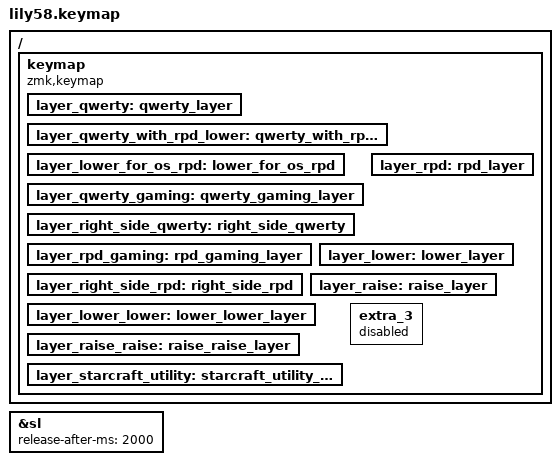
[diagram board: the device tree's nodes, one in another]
#include <behaviors.dtsi>
#include <dt-bindings/zmk/bt.h>
#include <dt-bindings/zmk/keys.h>

// for mouse configuration
#define ZMK_POINTING_DEFAULT_MOVE_VAL 1250
#define ZMK_POINTING_DEFAULT_SCRL_VAL 20
#include <dt-bindings/zmk/pointing.h>

#include "zmk-helpers/helper.h"

#include "keymaps/constants.dtsi"
#include "keymaps/combos/index.dtsi"
#include "keymaps/behaviours/mod-morphs/index.dtsi"
#include "keymaps/behaviours/mod-morphs/rpd-mod-morphs.dtsi"
#include "keymaps/behaviours/tap-holds/timeless-hrm.dtsi"
#include "keymaps/behaviours/tap-holds/index.dtsi"




/*                                      58 KEY MATRIX / LAYOUT MAPPING

  ╭────────────────────────────┬────────────────────────────╮ ╭─────────────────────────────┬─────────────────────────────╮
  │  0   1   2   3   4   5     │      6   7   8   9  10  11 │ │ LT5 LT4 LT3 LT2 LT1 LT0     │     RT0 RT1 RT2 RT3 RT4 RT5 │
  │ 12  13  14  15  16  17     │     18  19  20  21  22  23 │ │ LM5 LM4 LM3 LM2 LM1 LM0     │     RM0 RM1 RM2 RM3 RM4 RM5 │
  │ 24  25  26  27  28  29     │     30  31  32  33  34  35 │ │ LB5 LB4 LB3 LB2 LB1 LB0     │     RB0 RB1 RB2 RB3 RB4 RB5 │
  │ 36  37  38  39  40  41  42 │ 43  44  45  46  47  48  49 │ │ LF5 LF4 LF3 LF2 LF1 LF0 LEC │ REC RF0 RF1 RF2 RF3 RF4 RF5 │
  ╰───────────╮ 50  51  52  53 │ 54  55  56  57 ╭───────────╯ ╰───────────╮ LH3 LH2 LH1 LH0 │ RH0 RH1 RH2 RH3 ╭───────────╯
              ╰────────────────┴────────────────╯                         ╰─────────────────┴─────────────────╯             */


&sl {
    release-after-ms = <2000>;
};

/ {
    keymap {
        compatible = "zmk,keymap";

        layer_qwerty: qwerty_layer {};
        layer_qwerty_with_rpd_lower: qwerty_with_rpd_lower {};
        layer_lower_for_os_rpd: lower_for_os_rpd {};
        layer_qwerty_gaming: qwerty_gaming_layer {};
        layer_right_side_qwerty: right_side_qwerty {};
        layer_rpd: rpd_layer {};
        layer_rpd_gaming: rpd_gaming_layer {};
        layer_right_side_rpd: right_side_rpd {};
        layer_lower: lower_layer {};
        layer_raise: raise_layer {};
        layer_lower_lower: lower_lower_layer {};
        layer_raise_raise: raise_raise_layer {};
        layer_starcraft_utility: starcraft_utility_layer {};


        extra_3 { status = "reserved"; };
    };
};

#include "keymaps/layers/typing.dtsi"
#include "keymaps/layers/gaming.dtsi"
#include "keymaps/layers/utilities.dtsi"
